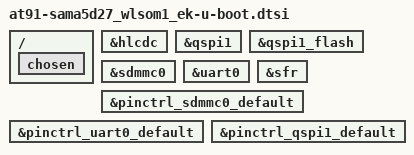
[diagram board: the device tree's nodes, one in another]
// SPDX-License-Identifier: (GPL-2.0+ OR MIT)
/*
 * at91-sama5d27_wlsom1_ek-u-boot.dts - Device Tree file for SAMA5D27 WLSOM1 EK
 *
 * Copyright (C) 2019 Microchip Technology Inc. and its subsidiaries
 *
 * Author: Eugen Hristev <eugen.hristev@microchip.com>
 */

/ {
	chosen {
		u-boot,dm-all;
	};
};

&hlcdc {
	u-boot,dm-all;
};

&qspi1 {
	u-boot,dm-all;
};

&qspi1_flash {
	u-boot,dm-all;
};

&sdmmc0 {
	u-boot,dm-all;
};

&uart0 {
	u-boot,dm-all;
};

&sfr {
	u-boot,dm-all;
};

&pinctrl_sdmmc0_default {
	u-boot,dm-all;
};

&pinctrl_uart0_default {
	u-boot,dm-all;
};

&pinctrl_qspi1_default {
	u-boot,dm-all;
};
